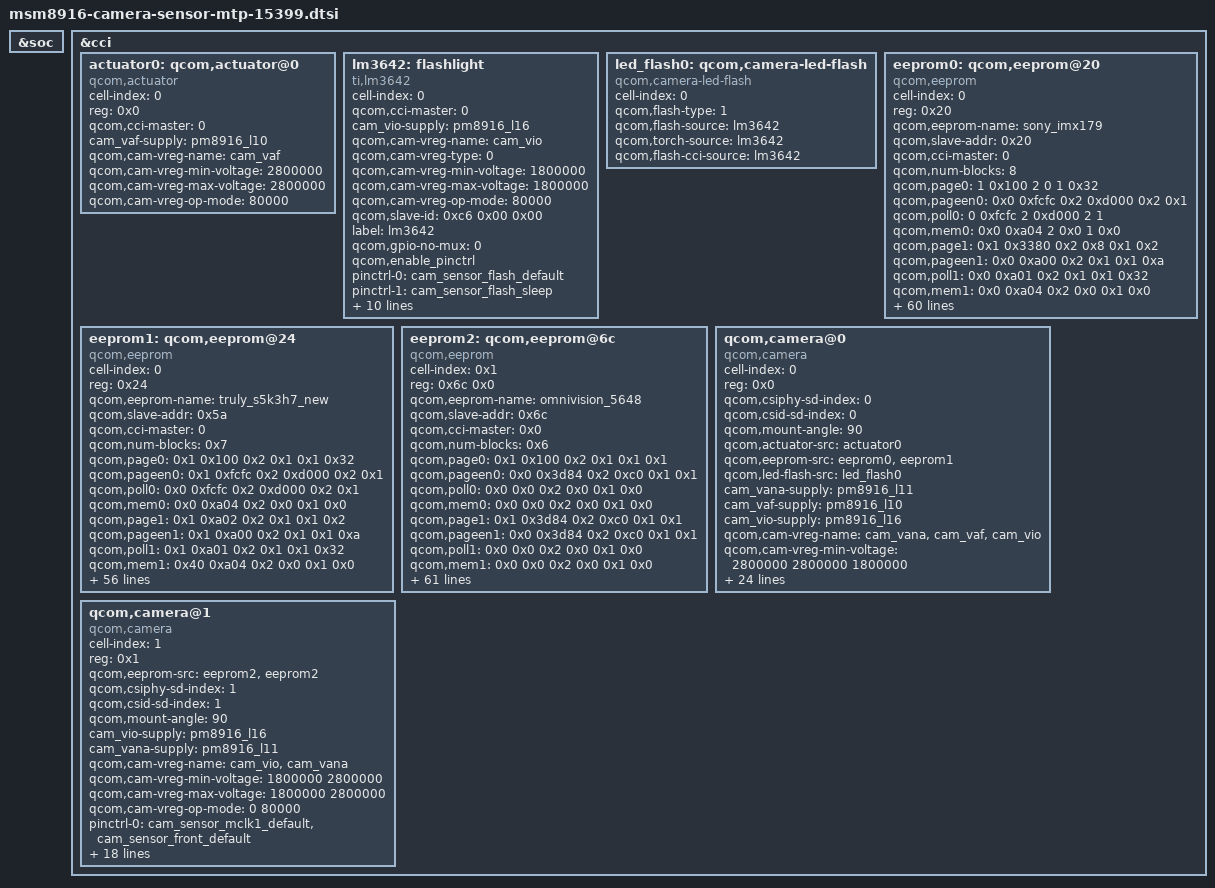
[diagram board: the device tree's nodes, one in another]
/* Copyright (c) 2020, The Linux Foundation. All rights reserved.
*  Copyright (c) 2020, the_shahnawaz_sheikh (sheikhshahnawaz41299).
*
* This program is free software; you can redistribute it and/or modify
* it under the terms of the GNU General Public License version 2 and
* only version 2 as published by the Free Software Foundation.
*
* This program is distributed in the hope that it will be useful,
* but WITHOUT ANY WARRANTY; without even the implied warranty of
* MERCHANTABILITY or FITNESS FOR A PARTICULAR PURPOSE.  See the
* GNU General Public License for more details.
*/

&soc {
      
	  /delete-node/ flash_tps61310;
	  /delete-node/ led_flash_0;
};

&cci {
	actuator0: qcom,actuator@0 {
		cell-index = <0>;
		reg = <0x0>;
		compatible = "qcom,actuator";
		qcom,cci-master = <0>;
		cam_vaf-supply = <&pm8916_l10>;
		qcom,cam-vreg-name = "cam_vaf";
		qcom,cam-vreg-min-voltage = <2800000>;
		qcom,cam-vreg-max-voltage = <2800000>;
		qcom,cam-vreg-op-mode = <80000>;
	};

    /delete-node/ qcom,led-flash@0;

	lm3642: flashlight {
		cell-index = <0>;
		compatible = "ti,lm3642";
		status = "okay";
		qcom,cci-master = <0>;
		cam_vio-supply = <&pm8916_l16>;
		qcom,cam-vreg-name = "cam_vio";
		qcom,cam-vreg-type = <0>;
		qcom,cam-vreg-min-voltage = <1800000>;
		qcom,cam-vreg-max-voltage = <1800000>;
		qcom,cam-vreg-op-mode = <80000>;
		qcom,slave-id = <0xc6 0x00 0x00>;
		label = "lm3642";
		qcom,gpio-no-mux = <0>;
		qcom,enable_pinctrl;
		pinctrl-names = "cam_flash_default", "cam_flash_suspend";
		pinctrl-0 = <&cam_sensor_flash_default>;
		pinctrl-1 = <&cam_sensor_flash_sleep>;
		gpios = <&msm_gpio 32 0>, <&msm_gpio 31 0>;
		qcom,gpio-flash-en = <0>;
		qcom,gpio-req-tbl-num = <0 1 2>;
		qcom,gpio-req-tbl-flags = <0 0 0>;
		qcom,gpio-req-tbl-label = "FLASH_EN", "FLASH_NOW";
		qcom,gpio-flash-now = <1>;
		qcom,current = <200>;
		qcom,max-current = <950>;
		linux,name = "flashlight";
		linux,default-trigger = "flashlight-trigger";
	};

	led_flash0: qcom,camera-led-flash {
		cell-index = <0>;
		compatible = "qcom,camera-led-flash";
		qcom,flash-type = <1>;
		qcom,flash-source = <&lm3642>;
		qcom,torch-source = <&lm3642>;
		qcom,flash-cci-source = <&lm3642>;
	};

    /delete-node/ qcom,eeprom@20;
	 /delete-node/ qcom,eeprom@1;

	eeprom0: qcom,eeprom@20 {
		cell-index = <0>;
		reg = <0x20>;
		qcom,eeprom-name = "sony_imx179";
		compatible = "qcom,eeprom";
		qcom,slave-addr = <0x20>;
		qcom,cci-master = <0>;
				
		qcom,num-blocks = <8>;
		qcom,page0 = <1 0x100 2 0 1 0x32>;
		qcom,pageen0 = <0x0 0xfcfc 0x2 0xd000 0x2 0x1>;
		qcom,poll0 = <0 0xfcfc 2 0xd000 2 1>;
		qcom,mem0 = <0x0 0xa04 2 0x0 1 0x0>;
				
		qcom,page1 = <0x1 0x3380 0x2 0x8 0x1 0x2>;
		qcom,pageen1 = <0x0 0xa00 0x2 0x1 0x1 0xa>;
		qcom,poll1 = <0x0 0xa01 0x2 0x1 0x1 0x32>;
		qcom,mem1 = <0x0 0xa04 0x2 0x0 0x1 0x0>;
				
		qcom,page2 = <0x1 0x3400 0x2 0x1 0x1 0x2>;
		qcom,pageen2 = <0x0 0xa00 0x2 0x1 0x1 0x1>;
		qcom,poll2 = <0x0 0xa01 0x2 0x1 0x1 0x1>;
		qcom,mem2 = <0x0 0xa04 0x2 0x0 0x1 0x0>;
				
		qcom,page3 = <0x1 0x3402 0x2 0x0 0x1 0x2>;
		qcom,pageen3 = <0x0 0xa00 0x2 0x1 0x1 0x1>;
		qcom,poll3 = <0x0 0xa01 0x2 0x1 0x1 0x1>;
		qcom,mem3 = <0x40 0x3404 0x2 0x0 0x1 0x0>;
				
		qcom,page4 = <0x1 0x3402 0x2 0x1 0x1 0x2>;
		qcom,pageen4 = <0x0 0xa00 0x2 0x1 0x1 0x1>;
		qcom,poll4 = <0x0 0xa01 0x2 0x1 0x1 0x1>;
		qcom,mem4 = <0x40 0x3404 0x2 0x0 0x1 0x0>;
				
		qcom,page5 = <0x1 0x3402 0x2 0x2 0x1 0x2>;
		qcom,pageen5 = <0x0 0xa00 0x2 0x1 0x1 0x1>;
		qcom,poll5 = <0x0 0xa01 0x2 0x1 0x1 0x1>;
		qcom,mem5 = <0x40 0x3404 0x2 0x0 0x1 0x0>;
				
		qcom,page6 = <0x1 0x3402 0x2 0x3 0x1 0x2>;
		qcom,pageen6 = <0x0 0xa00 0x2 0x1 0x1 0x1>;
		qcom,poll6 = <0x0 0xa01 0x2 0x1 0x1 0x1>;
		qcom,mem6 = <0x40 0x3404 0x2 0x0 0x1 0x0>;
				
		qcom,page7 = <0x1 0x3402 0x2 0x4 0x1 0x2>;
		qcom,pageen7 = <0x0 0xa00 0x2 0x1 0x1 0x1>;
		qcom,poll7 = <0x0 0xa01 0x2 0x1 0x1 0x1>;
		qcom,mem7 = <0x40 0x3404 0x2 0x0 0x1 0x0>;
				
		cam_vana-supply = <&pm8916_l11>;
		cam_vio-supply = <&pm8916_l16>;
		qcom,cam-vreg-name = "cam_vana", "cam_vio";
		qcom,cam-vreg-min-voltage = <0 1800000 2800000>;
		qcom,cam-vreg-max-voltage = <0 1800000 2800000>;
		qcom,cam-vreg-op-mode = <0 80000>;
		pinctrl-names = "cam_default", "cam_suspend";
		pinctrl-0 = <&cam_sensor_mclk0_default &cam_sensor_rear_default>;
		pinctrl-1 = <&cam_sensor_mclk0_sleep &cam_sensor_rear_sleep>;
		gpios = <&msm_gpio 26 0>,
			    <&msm_gpio 35 0>,
				 <&msm_gpio 20 0>,
				 <&msm_gpio 34 0>,
				 <&pm8916_gpios 2 0>;
		qcom,gpio-reset = <1>;
		qcom,gpio-standby = <2>;
		qcom,gpio-vdig = <3>;
		qcom,gpio-vio = <4>;
		qcom,gpio-req-tbl-num = <0 1 2 3 4>;
		qcom,gpio-req-tbl-flags = <1 0 0 0 0>;
		qcom,gpio-req-tbl-label = "CAMIF_MCLK0",
		                           "CAM_RESET0",
								   "CAM_STANDBY0",
								   "CAM_DVIG0",
								   "CAM_VDDIO0";
		qcom,gpio-set-tbl-delay = <1000 4000 4000 4000 5000>;
		qcom,csi-lane-assign = <0x4320>;
		qcom,csi-lane-mask = <0x1f>;
		qcom,cam-power-seq-type = "sensor_gpio", "sensor_vreg", "sensor_gpio", "sensor_vreg", "sensor_gpio", "sensor_clk";
		qcom,cam-power-seq-val = "sensor_gpio_vdig", "cam_vana", "sensor_gpio_vio", "cam_vio", "sensor_gpio_reset", "sensor_cam_mclk";
		qcom,cam-power-seq-cfg-val = <1 1 1 1 1 23880000>;
		qcom,cam-power-seq-delay = <10 10 5 10 5 5>;
		qcom,mclk-23880000;
		status = "ok";
		clocks = <&clock_gcc clk_mclk0_clk_src>,
				<&clock_gcc clk_gcc_camss_mclk0_clk>;
		clock-names = "cam_src_clk", "cam_clk";
	};

	eeprom1: qcom,eeprom@24 {
		cell-index = <0>;
		reg = <0x24>;
		qcom,eeprom-name = "truly_s5k3h7_new";
		compatible = "qcom,eeprom";
		qcom,slave-addr = <0x5a>;
		qcom,cci-master = <0>;
				
		qcom,num-blocks = <0x7>;
				
		qcom,page0 = <0x1 0x100 0x2 0x1 0x1 0x32>;
		qcom,pageen0 = <0x1 0xfcfc 0x2 0xd000 0x2 0x1>;
		qcom,poll0 = <0x0 0xfcfc 0x2 0xd000 0x2 0x1>;
		qcom,mem0 = <0x0 0xa04 0x2 0x0 0x1 0x0>;
		
		qcom,page1 = <0x1 0xa02 0x2 0x1 0x1 0x2>;
		qcom,pageen1 = <0x1 0xa00 0x2 0x1 0x1 0xa>;
		qcom,poll1 = <0x1 0xa01 0x2 0x1 0x1 0x32>;
		qcom,mem1 = <0x40 0xa04 0x2 0x0 0x1 0x0>;
				
		qcom,page2 = <0x1 0xa00 0x2 0x0 0x1 0x1>;
		qcom,pageen2 = <0x0 0xa02 0x2 0x2 0x1 0x14>;
		qcom,poll2 = <0x0 0xa00 0x2 0x1 0x1 0x1>;
		qcom,mem2 = <0x0 0xa04 0x2 0x0 0x1 0x0>;
				
		qcom,page3 = <0x1 0xa02 0x2 0x2 0x1 0x2>;
		qcom,pageen3 = <0x1 0xa00 0x2 0x1 0x1 0xa>;
		qcom,poll3 = <0x1 0xa01 0x2 0x1 0x1 0x32>;
		qcom,mem3 = <0x40 0xa04 0x2 0x0 0x1 0x0>;
				
		qcom,page4 = <0x1 0xa00 0x2 0x0 0x1 0x2>;
		qcom,pageen4 = <0x0 0xa00 0x2 0x1 0x1 0x1>;
		qcom,poll4 = <0x0 0xa01 0x2 0x1 0x1 0x32>;
		qcom,mem4 = <0x0 0xa04 0x2 0x0 0x1 0x0>;
				
		qcom,page5 = <0x1 0xa02 0x2 0x3 0x1 0x2>;
		qcom,pageen5 = <0x1 0xa00 0x2 0x1 0x1 0xa>;
		qcom,poll5 = <0x1 0xa01 0x2 0x1 0x1 0x32>;
		qcom,mem5 = <0x40 0xa04 0x2 0x0 0x1 0x0>;
				
		qcom,page6 = <0x1 0xa00 0x2 0x0 0x1 0x2>;
		qcom,pageen6 = <0x0 0xa00 0x2 0x1 0x1 0x1>;
		qcom,poll6 = <0x0 0xa01 0x2 0x1 0x1 0x1>;
		qcom,mem6 = <0x0 0xa04 0x2 0x0 0x1 0x0>;
				
		cam_vana-supply = <&pm8916_l11>;
		cam_vio-supply = <&pm8916_l16>;
		qcom,cam-vreg-name = "cam_vana", "cam_vio";
		qcom,cam-vreg-min-voltage = <0 1800000 2800000 0>;
		qcom,cam-vreg-max-voltage = <0 1800000 2800000 0>;
		qcom,cam-vreg-op-mode = <80000 0>;
		pinctrl-names = "cam_default", "cam_suspend";
		pinctrl-0 = <&cam_sensor_mclk0_default
				              &cam_sensor_rear_default>;
		pinctrl-1 = <&cam_sensor_mclk0_sleep 
				               &cam_sensor_rear_sleep>;
		gpios = <&msm_gpio 26 0>,
				         <&msm_gpio 35 0>,
						 <&msm_gpio 20 0>,
						 <&msm_gpio 34 0>,
						 <&pm8916_gpios 2 0>;
		qcom,gpio-reset = <1>;
		qcom,gpio-standby = <2>;
		qcom,gpio-vdig = <3>;
		qcom,gpio-vio = <4>;
		qcom,gpio-req-tbl-num = <0 1 2 3 4>;
		qcom,gpio-req-tbl-flags = <1 0 0 0 0>;
		qcom,gpio-req-tbl-label = "CAMIF_MCLK0", "CAM_RESET0", "CAM_STANDBY0", "CAM_DVIG0", "CAM_VDDIO0";
		qcom,gpio-set-tbl-delay = <1000 4000 4000 4000 5000>;
		qcom,csi-lane-assign = <0x4320>;
		qcom,csi-lane-mask = <0x1f>;
		qcom,cam-power-seq-type = "sensor_gpio", "sensor_vreg", "sensor_gpio", "sensor_vreg", "sensor_gpio", "sensor_clk";
		qcom,cam-power-seq-val = "sensor_gpio_vdig", "cam_vana", "sensor_gpio_vio", "cam_vio", "sensor_gpio_reset", "sensor_cam_mclk";
		qcom,cam-power-seq-cfg-val = <1 1 1 1 1 23880000>;
		qcom,cam-power-seq-delay = <10 10 5 10 5 5>;
		qcom,mclk-23880000;
		status = "ok";
		clocks = <&clock_gcc clk_mclk1_clk_src>,
				         <&clock_gcc clk_gcc_camss_mclk1_clk>;
		clock-names = "cam_src_clk", "cam_clk";
	};

	eeprom2: qcom,eeprom@6c {
		cell-index = <0x1>;
		reg = <0x6c 0x0>;
		qcom,eeprom-name = "omnivision_5648";
		qcom,slave-addr = <0x6c>;
		qcom,cci-master = <0x0>;
		
		compatible = "qcom,eeprom";
		qcom,num-blocks = <0x6>;
				
		qcom,page0 = <0x1 0x100 0x2 0x1 0x1 0x1>;
		qcom,pageen0 = <0x0 0x3d84 0x2 0xc0 0x1 0x1>;
		qcom,poll0 = <0x0 0x0 0x2 0x0 0x1 0x0>;
		qcom,mem0 = <0x0 0x0 0x2 0x0 0x1 0x0>;
				
		qcom,page1 = <0x1 0x3d84 0x2 0xc0 0x1 0x1>;
		qcom,pageen1 = <0x0 0x3d84 0x2 0xc0 0x1 0x1>;
		qcom,poll1 = <0x0 0x0 0x2 0x0 0x1 0x0>;
		qcom,mem1 = <0x0 0x0 0x2 0x0 0x1 0x0>;
				
		qcom,page2 = <0x1 0x3d85 0x2 0x0 0x1 0x1>;
		qcom,pageen2 = <0x0 0x3d84 0x2 0xc0 0x1 0x1>;
		qcom,poll2 = <0x0 0x0 0x2 0x0 0x1 0x0>;
		qcom,mem2 = <0x0 0x0 0x2 0x0 0x1 0x0>;
		
		qcom,page3 = <0x1 0x3d86 0x2 0xf 0x1 0x1>;
		qcom,pageen3 = <0x1 0x3d81 0x2 0x1 0x1 0xa>;
		qcom,poll3 = <0x0 0x0 0x2 0x0 0x1 0x0>;
		qcom,mem3 = <0x10 0x3d00 0x2 0x0 0x1 0x0>;
				
		qcom,page4 = <0x1 0x3d85 0x2 0x10 0x1 0x1>;
		qcom,pageen4 = <0x0 0x3d89 0x2 0x10 0x1 0x1>;
		qcom,poll4 = <0x0 0x0 0x2 0x0 0x1 0x0>;
		qcom,mem4 = <0x0 0x0 0x2 0x0 0x1 0x0>;
				
		qcom,page5 = <0x1 0x3d86 0x2 0x1f 0x1 0x1>;
		qcom,pageen5 = <0x1 0x3d81 0x2 0x1 0x1 0xa>;
		qcom,poll5 = <0x0 0x0 0x2 0x0 0x1 0x0>;
		qcom,mem5 = <0x10 0x3d00 0x2 0x0 0x1 0x0>;
				
		qcom,page6 = <0x1 0x3d8b 0x2 0x1b 0x1 0x1>;
		qcom,pageen6 = <0x0 0x3d89 0x2 0x10 0x1 0x1>;
		qcom,poll6 = <0x0 0x0 0x2 0x0 0x1 0x0>;
		qcom,mem6 = <0x0 0x0 0x2 0x0 0x1 0x0>;
				
		qcom,page7 = <0x1 0x3d81 0x2 0x1 0x1 0x2d>;
		qcom,pageen7 = <0x0 0x3d81 0x2 0x1 0x1 0x2d>;
		qcom,poll7 = <0x0 0x0 0x2 0x0 0x1 0x0>;
		qcom,mem7 = <0x10 0x700c 0x2 0x0 0x1 0x0>;
				
		cam_vio-supply = <&pm8916_l16>;
		cam_vana-supply = <&pm8916_l11>;
		qcom,cam-vreg-name = "cam_vio", "cam_vana";
		qcom,cam-vreg-min-voltage = <1800000 2800000>;
		qcom,cam-vreg-max-voltage = <1800000 2800000>;
		qcom,cam-vreg-op-mode = <0 80000>;
		pinctrl-names = "cam_default", "cam_suspend";
		pinctrl-0 =  <&cam_sensor_mclk1_default 
				             &cam_sensor_front_default>;
		pinctrl-1 = <&cam_sensor_mclk1_sleep 
				             &cam_sensor_front_sleep>;
		gpios = <&msm_gpio 27 0>,
				         <&msm_gpio 28 0>,
						<&msm_gpio 33 0 >,
						 <&msm_gpio 34 0>,
						 <&pm8916_gpios 2 0>;
		qcom,gpio-reset = <1>;
		qcom,gpio-standby = <2>;
		qcom,gpio-vdig = <3>;
		qcom,gpio-vio = <4>;
		qcom,gpio-req-tbl-num = <0 1 2 3 4>;
		qcom,gpio-req-tbl-flags = <1 0 0 0 0>;
		qcom,gpio-req-tbl-label = "CAMIF_MCLK", "CAM_RESET1", "CAM_STANDBY1", "CAM_VDIG1", "CAM_VDDIO1";
		status = "ok";
		clocks = <&clock_gcc clk_mclk1_clk_src>,
				<&clock_gcc clk_gcc_camss_mclk1_clk>;
		clock-names = "cam_src_clk", "cam_clk";
		qcom,gpio-set-tbl-delay = <1000 10000 30000 10000 10000>;
		qcom,csi-lane-assign = <0x4320>;
		qcom,csi-lane-mask = <0x1f>;
		qcom,cam-power-seq-type = "sensor_vreg", "sensor_vreg", "sensor_gpio", "sensor_gpio", "sensor_gpio", "sensor_gpio", "sensor_clk";
		qcom,cam-power-seq-val = "cam_vana", "cam_vio", "sensor_gpio_vio", "sensor_gpio_vdig", "sensor_gpio_reset", "sensor_gpio_standby", "sensor_cam_mclk";
		qcom,cam-power-seq-cfg-val = <1 1 1 1 1 1 23880000>;
		qcom,cam-power-seq-delay = <1 5 5 1 5 5 10>;
	};
			
			
		/delete-node/ qcom,camera@78;
	    /delete-node/ qcom,camera@1;
	    /delete-node/ qcom,camera@0;
		
		
	qcom,camera@0 {
		cell-index = <0>;
		compatible = "qcom,camera";
		reg = <0x0>;
		qcom,csiphy-sd-index = <0>;
		qcom,csid-sd-index = <0>;
		qcom,mount-angle = <90>;
		qcom,actuator-src = <&actuator0>;
		qcom,eeprom-src = <&eeprom0 &eeprom1>;
		qcom,led-flash-src = <&led_flash0>;
		cam_vana-supply = <&pm8916_l11>;
		cam_vaf-supply = <&pm8916_l10>;
		cam_vio-supply = <&pm8916_l16>;
		qcom,cam-vreg-name = "cam_vana", "cam_vaf", "cam_vio";
		qcom,cam-vreg-min-voltage = <2800000 2800000 1800000>;
		qcom,cam-vreg-max-voltage = <2800000 2800000 1800000>;
		qcom,cam-vreg-op-mode = <80000 100000 0>;
		pinctrl-names = "cam_default", "cam_suspend";
		pinctrl-0 = <&cam_sensor_mclk0_default
				&cam_sensor_rear_default>;
		pinctrl-1 = <&cam_sensor_mclk0_sleep &cam_sensor_rear_sleep>;
		gpios = <&msm_gpio 26 0>,
		         <&msm_gpio 35 0>,
				 <&msm_gpio 20 0>,
				 <&msm_gpio 34 0>,
				 <&pm8916_gpios 2 0>;
		qcom,gpio-reset = <1>;
		qcom,gpio-standby = <2>;
		qcom,gpio-vdig = <3>;
		qcom,gpio-vio = <4>;
		qcom,gpio-req-tbl-num = <0 1 2 3 4>;
		qcom,gpio-req-tbl-flags = <1 0 0 0 0>;
		qcom,gpio-req-tbl-label = "CAMIF_MCLK0", "CAM_RESET0", "CAM_STANDBY0", "CAM_VDIG0", "CAM_VDDIO0";
		qcom,sensor-position = <0>;
		qcom,sensor-mode = <0>;
		qcom,cci-master = <0>;
		qcom,mclk-23880000;
		status = "ok";
		clocks = <&clock_gcc clk_mclk0_clk_src>,
				<&clock_gcc clk_gcc_camss_mclk0_clk>;
		clock-names = "cam_src_clk", "cam_clk";
	};

	qcom,camera@1 {
		cell-index = <1>;
		compatible = "qcom,camera";
		reg = <0x1>;
		qcom,eeprom-src = <&eeprom2 &eeprom2>;
		qcom,csiphy-sd-index = <1>;
		qcom,csid-sd-index = <1>;
		qcom,mount-angle = <90>;
		cam_vio-supply = <&pm8916_l16>;
		cam_vana-supply = <&pm8916_l11>;
		qcom,cam-vreg-name = "cam_vio", "cam_vana";
		qcom,cam-vreg-min-voltage = <1800000 2800000>;
		qcom,cam-vreg-max-voltage = <1800000 2800000>;
		qcom,cam-vreg-op-mode = <0 80000>;
		pinctrl-names = "cam_default", "cam_suspend";
		pinctrl-0 = <&cam_sensor_mclk1_default
				&cam_sensor_front_default>;
		pinctrl-1 = <&cam_sensor_mclk1_sleep &cam_sensor_front_sleep>;
		gpios = <&msm_gpio 27 0>,
		         <&msm_gpio 28 0>,
				 <&msm_gpio 33 0>,
				 <&msm_gpio 34 0>,
				 <&pm8916_gpios 2 0>;
		qcom,gpio-reset = <1>;
		qcom,gpio-standby = <2>;
		qcom,gpio-vdig = <3>;
		qcom,gpio-vio = <4>;
		qcom,gpio-req-tbl-num = <0 1 2 3 4>;
		qcom,gpio-req-tbl-flags = <1 0 0 0 0>;
		qcom,gpio-req-tbl-label = "CAMIF_MCLK", "CAM_RESET1", "CAM_STANDBY1", "CAM_VDIG1", "CAM_VDDIO1";
		qcom,cci-master = <0>;
		qcom,sensor-position = <1>;
		qcom,mclk-23880000;
		status = "ok";
		clocks = <&clock_gcc clk_mclk1_clk_src>,
				<&clock_gcc clk_gcc_camss_mclk1_clk>;
		clock-names = "cam_src_clk", "cam_clk";
	};
};
